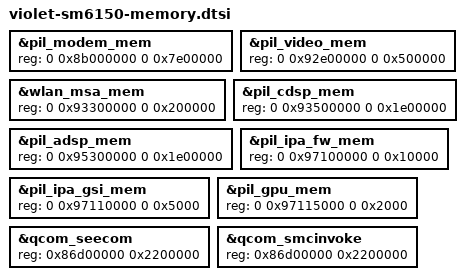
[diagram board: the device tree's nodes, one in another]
/* Copyright (c) 2020, The Linux Foundation. All rights reserved.
 *
 * This program is free software; you can redistribute it and/or modify
 * it under the terms of the GNU General Public License version 2 and
 * only version 2 as published by the Free Software Foundation.
 *
 * This program is distributed in the hope that it will be useful,
 * but WITHOUT ANY WARRANTY; without even the implied warranty of
 * MERCHANTABILITY or FITNESS FOR A PARTICULAR PURPOSE.  See the
 * GNU General Public License for more details.
 */

&pil_modem_mem {
    reg = <0 0x8b000000 0 0x7e00000>;
};

&pil_video_mem {
    reg = <0 0x92e00000 0 0x500000>;
};

&wlan_msa_mem {
    reg = <0 0x93300000 0 0x200000>;
};

&pil_cdsp_mem {
    reg = <0 0x93500000 0 0x1e00000>;
};

&pil_adsp_mem {
    reg = <0 0x95300000 0 0x1e00000>;
};

&pil_ipa_fw_mem {
    reg = <0 0x97100000 0 0x10000>;
};

&pil_ipa_gsi_mem {
    reg = <0 0x97110000 0 0x5000>;
};

&pil_gpu_mem {
    reg = <0 0x97115000 0 0x2000>;
};

/* Override TZ App (secapp) memory region 0xe00000 -> 0x2200000 */

&qcom_seecom {
	reg = <0x86d00000 0x2200000>;
};

&qcom_smcinvoke {
	reg = <0x86d00000 0x2200000>;
};
